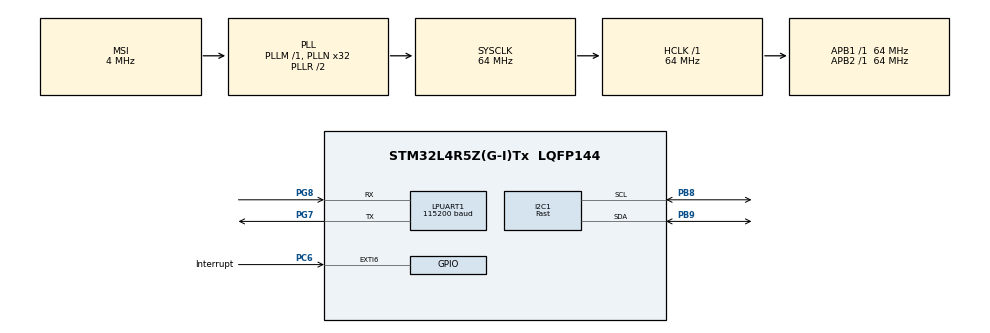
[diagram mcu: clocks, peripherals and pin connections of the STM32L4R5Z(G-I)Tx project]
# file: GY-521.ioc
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Mcu.Family=STM32L4
RCC.MSI_VALUE=4000000
PG8.Mode=Asynchronous
RCC.CortexFreq_Value=64000000
PG7.Signal=LPUART1_TX
I2C1.I2C_Speed_Mode=I2C_Fast
PG8.Signal=LPUART1_RX
PC6.Signal=GPXTI6
PC6.GPIO_Label=Interrupt
LPUART1.WordLength=UART_WORDLENGTH_8B
RCC.SYSCLKSource=RCC_SYSCLKSOURCE_PLLCLK
ProjectManager.StackSize=0x400
ProjectManager.TargetToolchain=STM32CubeIDE
RCC.HCLKFreq_Value=64000000
PB9.Mode=I2C
RCC.APB2TimFreq_Value=64000000
I2C1.Timing=0x00602173
PG7.Mode=Asynchronous
RCC.LSE_VALUE=32768
RCC.AHBFreq_Value=64000000
RCC.HSE_VALUE=8000000
board=custom
RCC.VCOOutputFreq_Value=128000000
RCC.APB2Freq_Value=64000000
Mcu.Name=STM32L4R5Z(G-I)Tx
LPUART1.BaudRate=115200
RCC.SYSCLKFreq_VALUE=64000000
Mcu.Package=LQFP144
PB9.Signal=I2C1_SDA
ProjectManager.HeapSize=0x200
RCC.HSI_VALUE=16000000
NVIC.PriorityGroup=NVIC_PRIORITYGROUP_4
PB8.Mode=I2C
RCC.PLLN=32
RCC.APB1TimFreq_Value=64000000
PB8.Signal=I2C1_SCL
RCC.APB1Freq_Value=64000000
RCC.HSI48_VALUE=48000000

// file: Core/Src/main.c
/* USER CODE BEGIN Header */
/**
  ******************************************************************************
  * @file           : main.c
  * @brief          : Main program body
  ******************************************************************************
  * @attention
  *
  * <h2><center>&copy; Copyright (c) 2021 STMicroelectronics.
  * All rights reserved.</center></h2>
  *
  * This software component is licensed by ST under BSD 3-Clause license,
  * the "License"; You may not use this file except in compliance with the
  * License. You may obtain a copy of the License at:
  *                        opensource.org/licenses/BSD-3-Clause
  *
  ******************************************************************************
  */
/* USER CODE END Header */
#include "main.h"

/* USER CODE BEGIN Includes */
#include "stm32l4xx_hal.h"
#include "defines.h"
#include "tm_stm32_disco.h"
#include "tm_stm32_delay.h"
#include "tm_stm32_mpu6050.h"
/* USER CODE END Includes */

I2C_HandleTypeDef hi2c1;

UART_HandleTypeDef hlpuart1;

void SystemClock_Config(void);
static void MX_GPIO_Init(void);
static void MX_I2C1_Init(void);
static void MX_LPUART1_UART_Init(void);

/* USER CODE BEGIN 0 */
TM_MPU6050_t MPU6050;
/* USER CODE END 0 */

int main(void)
{

  /* MCU Configuration--------------------------------------------------------*/

  /* Reset of all peripherals, Initializes the Flash interface and the Systick. */
  HAL_Init();

  /* Configure the system clock */
  SystemClock_Config();

  /* Initialize all configured peripherals */
  MX_GPIO_Init();
  MX_I2C1_Init();
  MX_LPUART1_UART_Init();
  /* USER CODE BEGIN 2 */
  TM_DISCO_LedInit();

  	/* Init button */
  	TM_DISCO_ButtonInit();

  	/* For pinouts, check TM_MPU6050 library */

  	/* Try to init MPU6050, device address is 0xD0, AD0 pin is set to low */
  	if (TM_MPU6050_Init(&MPU6050, TM_MPU6050_Device_0, TM_MPU6050_Accelerometer_8G, TM_MPU6050_Gyroscope_250s) == TM_MPU6050_Result_Ok) {
  		/* Green LED on */
  		TM_DISCO_LedOn(LED_GREEN);
  	}
  /* USER CODE END 2 */

  /* Infinite loop */
  /* USER CODE BEGIN WHILE */
  while (1)
  {
	  /* Read everything from device */
	  		TM_MPU6050_ReadAll(&MPU6050);

	  		/* Raw data are available for use as needed */
	  		//MPU6050.Accelerometer_X;
	  		//MPU6050.Accelerometer_Y;
	  		//MPU6050.Accelerometer_Z;
	  		//MPU6050.Gyroscope_X;
	  		//MPU6050.Gyroscope_Y;
	  		//MPU6050.Gyroscope_Z;
	  		//MPU6050.Temperature;

	  		/* Delay a little */
	  		Delayms(1);
    /* USER CODE END WHILE */

  }
}

void SystemClock_Config(void)
{
  RCC_OscInitTypeDef RCC_OscInitStruct = {0};
  RCC_ClkInitTypeDef RCC_ClkInitStruct = {0};
  RCC_PeriphCLKInitTypeDef PeriphClkInit = {0};

  /** Configure the main internal regulator output voltage
  */
  if (HAL_PWREx_ControlVoltageScaling(PWR_REGULATOR_VOLTAGE_SCALE1) != HAL_OK)
  {
    Error_Handler();
  }
  /** Initializes the RCC Oscillators according to the specified parameters
  * in the RCC_OscInitTypeDef structure.
  */
  RCC_OscInitStruct.OscillatorType = RCC_OSCILLATORTYPE_MSI;
  RCC_OscInitStruct.MSIState = RCC_MSI_ON;
  RCC_OscInitStruct.MSICalibrationValue = 0;
  RCC_OscInitStruct.MSIClockRange = RCC_MSIRANGE_6;
  RCC_OscInitStruct.PLL.PLLState = RCC_PLL_ON;
  RCC_OscInitStruct.PLL.PLLSource = RCC_PLLSOURCE_MSI;
  RCC_OscInitStruct.PLL.PLLM = 1;
  RCC_OscInitStruct.PLL.PLLN = 32;
  RCC_OscInitStruct.PLL.PLLP = RCC_PLLP_DIV2;
  RCC_OscInitStruct.PLL.PLLQ = RCC_PLLQ_DIV2;
  RCC_OscInitStruct.PLL.PLLR = RCC_PLLR_DIV2;
  if (HAL_RCC_OscConfig(&RCC_OscInitStruct) != HAL_OK)
  {
    Error_Handler();
  }
  /** Initializes the CPU, AHB and APB buses clocks
  */
  RCC_ClkInitStruct.ClockType = RCC_CLOCKTYPE_HCLK|RCC_CLOCKTYPE_SYSCLK
                              |RCC_CLOCKTYPE_PCLK1|RCC_CLOCKTYPE_PCLK2;
  RCC_ClkInitStruct.SYSCLKSource = RCC_SYSCLKSOURCE_PLLCLK;
  RCC_ClkInitStruct.AHBCLKDivider = RCC_SYSCLK_DIV1;
  RCC_ClkInitStruct.APB1CLKDivider = RCC_HCLK_DIV1;
  RCC_ClkInitStruct.APB2CLKDivider = RCC_HCLK_DIV1;

  if (HAL_RCC_ClockConfig(&RCC_ClkInitStruct, FLASH_LATENCY_3) != HAL_OK)
  {
    Error_Handler();
  }
  PeriphClkInit.PeriphClockSelection = RCC_PERIPHCLK_LPUART1|RCC_PERIPHCLK_I2C1;
  PeriphClkInit.Lpuart1ClockSelection = RCC_LPUART1CLKSOURCE_PCLK1;
  PeriphClkInit.I2c1ClockSelection = RCC_I2C1CLKSOURCE_PCLK1;
  if (HAL_RCCEx_PeriphCLKConfig(&PeriphClkInit) != HAL_OK)
  {
    Error_Handler();
  }
}

static void MX_I2C1_Init(void)
{

  hi2c1.Instance = I2C1;
  hi2c1.Init.Timing = 0x00602173;
  hi2c1.Init.OwnAddress1 = 0;
  hi2c1.Init.AddressingMode = I2C_ADDRESSINGMODE_7BIT;
  hi2c1.Init.DualAddressMode = I2C_DUALADDRESS_DISABLE;
  hi2c1.Init.OwnAddress2 = 0;
  hi2c1.Init.OwnAddress2Masks = I2C_OA2_NOMASK;
  hi2c1.Init.GeneralCallMode = I2C_GENERALCALL_DISABLE;
  hi2c1.Init.NoStretchMode = I2C_NOSTRETCH_DISABLE;
  if (HAL_I2C_Init(&hi2c1) != HAL_OK)
  {
    Error_Handler();
  }
  /** Configure Analogue filter
  */
  if (HAL_I2CEx_ConfigAnalogFilter(&hi2c1, I2C_ANALOGFILTER_ENABLE) != HAL_OK)
  {
    Error_Handler();
  }
  /** Configure Digital filter
  */
  if (HAL_I2CEx_ConfigDigitalFilter(&hi2c1, 0) != HAL_OK)
  {
    Error_Handler();
  }

}

static void MX_LPUART1_UART_Init(void)
{

  hlpuart1.Instance = LPUART1;
  hlpuart1.Init.BaudRate = 115200;
  hlpuart1.Init.WordLength = UART_WORDLENGTH_8B;
  hlpuart1.Init.StopBits = UART_STOPBITS_1;
  hlpuart1.Init.Parity = UART_PARITY_NONE;
  hlpuart1.Init.Mode = UART_MODE_TX_RX;
  hlpuart1.Init.HwFlowCtl = UART_HWCONTROL_NONE;
  hlpuart1.Init.OneBitSampling = UART_ONE_BIT_SAMPLE_DISABLE;
  hlpuart1.Init.ClockPrescaler = UART_PRESCALER_DIV1;
  hlpuart1.AdvancedInit.AdvFeatureInit = UART_ADVFEATURE_NO_INIT;
  hlpuart1.FifoMode = UART_FIFOMODE_DISABLE;
  if (HAL_UART_Init(&hlpuart1) != HAL_OK)
  {
    Error_Handler();
  }
  if (HAL_UARTEx_SetTxFifoThreshold(&hlpuart1, UART_TXFIFO_THRESHOLD_1_8) != HAL_OK)
  {
    Error_Handler();
  }
  if (HAL_UARTEx_SetRxFifoThreshold(&hlpuart1, UART_RXFIFO_THRESHOLD_1_8) != HAL_OK)
  {
    Error_Handler();
  }
  if (HAL_UARTEx_DisableFifoMode(&hlpuart1) != HAL_OK)
  {
    Error_Handler();
  }

}

static void MX_GPIO_Init(void)
{
  GPIO_InitTypeDef GPIO_InitStruct = {0};

  /* GPIO Ports Clock Enable */
  __HAL_RCC_GPIOG_CLK_ENABLE();
  HAL_PWREx_EnableVddIO2();
  __HAL_RCC_GPIOC_CLK_ENABLE();
  __HAL_RCC_GPIOB_CLK_ENABLE();

  /*Configure GPIO pin : Interrupt_Pin */
  GPIO_InitStruct.Pin = Interrupt_Pin;
  GPIO_InitStruct.Mode = GPIO_MODE_IT_RISING;
  GPIO_InitStruct.Pull = GPIO_NOPULL;
  HAL_GPIO_Init(Interrupt_GPIO_Port, &GPIO_InitStruct);

}

void Error_Handler(void)
{
  __disable_irq();
  while (1)
  {
  }
}

/************************ (C) COPYRIGHT STMicroelectronics *****END OF FILE****/
